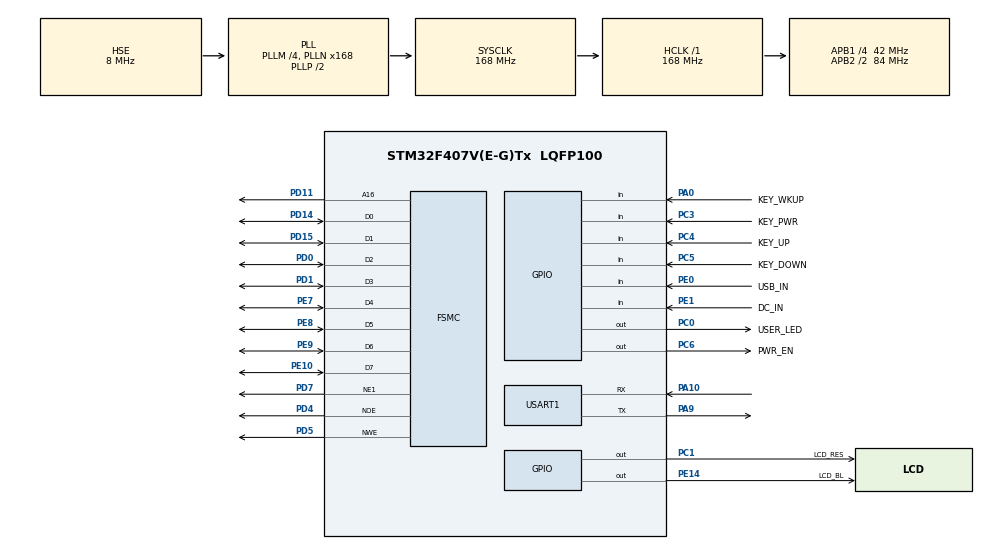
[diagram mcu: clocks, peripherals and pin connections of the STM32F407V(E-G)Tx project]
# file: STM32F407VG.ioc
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FSMC.AddressSetupTime1=1
FSMC.BusTurnAroundDuration1=1
FSMC.DataSetupTime1=5
FSMC.ExtendedAddressSetupTime1=1
FSMC.ExtendedBusTurnAroundDuration1=1
FSMC.ExtendedDataSetupTime1=2
FSMC.ExtendedMode1=FSMC_EXTENDED_MODE_ENABLE
Mcu.Family=STM32F4
Mcu.Name=STM32F407V(E-G)Tx
Mcu.Package=LQFP100
NVIC.PriorityGroup=NVIC_PRIORITYGROUP_4
PA0-WKUP.GPIO_Label=KEY_WKUP
PA0-WKUP.Signal=GPIO_Input
PA10.Mode=Asynchronous
PA10.Signal=USART1_RX
PA13.Mode=Serial_Wire
PA13.Signal=SYS_JTMS-SWDIO
PA14.Mode=Serial_Wire
PA14.Signal=SYS_JTCK-SWCLK
PA9.Mode=Asynchronous
PA9.Signal=USART1_TX
PC0.GPIO_Label=USER_LED
PC0.GPIO_ModeDefaultOutputPP=GPIO_MODE_OUTPUT_PP
PC0.GPIO_PuPd=GPIO_PULLUP
PC0.GPIO_Speed=GPIO_SPEED_FREQ_VERY_HIGH
PC0.PinState=GPIO_PIN_SET
PC0.Signal=GPIO_Output
PC1.GPIO_Label=LCD_RES
PC1.GPIO_PuPd=GPIO_PULLUP
PC1.GPIO_Speed=GPIO_SPEED_FREQ_VERY_HIGH
PC1.PinState=GPIO_PIN_SET
PC1.Signal=GPIO_Output
PC14-OSC32_IN.Mode=LSE-External-Oscillator
PC14-OSC32_IN.Signal=RCC_OSC32_IN
PC15-OSC32_OUT.Mode=LSE-External-Oscillator
PC15-OSC32_OUT.Signal=RCC_OSC32_OUT
PC3.GPIO_Label=KEY_PWR
PC3.GPIO_PuPd=GPIO_PULLUP
PC3.Signal=GPIO_Input
PC4.GPIO_Label=KEY_UP
PC4.GPIO_PuPd=GPIO_PULLUP
PC4.Signal=GPIO_Input
PC5.GPIO_Label=KEY_DOWN
PC5.GPIO_PuPd=GPIO_PULLUP
PC5.Signal=GPIO_Input
PC6.GPIO_Label=PWR_EN
PC6.GPIO_PuPd=GPIO_PULLDOWN
PC6.GPIO_Speed=GPIO_SPEED_FREQ_VERY_HIGH
PC6.PinState=GPIO_PIN_RESET
PC6.Signal=GPIO_Output
PD0.Mode=8b-d1
PD0.Signal=FSMC_D2
PD1.Mode=8b-d1
PD1.Signal=FSMC_D3
PD11.Mode=A16_1
PD11.Signal=FSMC_A16
PD14.Mode=8b-d1
PD14.Signal=FSMC_D0
PD15.Mode=8b-d1
PD15.Signal=FSMC_D1
PD4.Mode=Lcd1
PD4.Signal=FSMC_NOE
PD5.Mode=Lcd1
PD5.Signal=FSMC_NWE
PD7.Mode=NorPsramChipSelect1_1
PD7.Signal=FSMC_NE1
PE0.GPIO_Label=USB_IN
PE0.Signal=GPIO_Input
PE1.GPIO_Label=DC_IN
PE1.Signal=GPIO_Input
PE10.Mode=8b-d1
PE10.Signal=FSMC_D7
PE14.GPIO_Label=LCD_BL
PE14.GPIO_ModeDefaultOutputPP=GPIO_MODE_OUTPUT_PP
PE14.GPIO_PuPd=GPIO_PULLDOWN
PE14.GPIO_Speed=GPIO_SPEED_FREQ_VERY_HIGH
PE14.PinState=GPIO_PIN_RESET
PE14.Signal=GPIO_Output
PE7.Mode=8b-d1
PE7.Signal=FSMC_D4
PE8.Mode=8b-d1
PE8.Signal=FSMC_D5
PE9.Mode=8b-d1
PE9.Signal=FSMC_D6
PH0-OSC_IN.Mode=HSE-External-Oscillator
PH0-OSC_IN.Signal=RCC_OSC_IN
PH1-OSC_OUT.Mode=HSE-External-Oscillator
PH1-OSC_OUT.Signal=RCC_OSC_OUT
ProjectManager.HeapSize=0x200
ProjectManager.StackSize=0x400
ProjectManager.TargetToolchain=MDK-ARM V5.32
RCC.48MHZClocksFreq_Value=84000000
RCC.AHBFreq_Value=168000000
RCC.APB1CLKDivider=RCC_HCLK_DIV4
RCC.APB1Freq_Value=42000000
RCC.APB1TimFreq_Value=84000000
RCC.APB2CLKDivider=RCC_HCLK_DIV2
RCC.APB2Freq_Value=84000000
RCC.APB2TimFreq_Value=168000000
RCC.CortexFreq_Value=168000000
RCC.HCLKFreq_Value=168000000
RCC.HSE_VALUE=8000000
RCC.HSI_VALUE=16000000
RCC.PLLM=4
RCC.PLLN=168
RCC.PLLSourceVirtual=RCC_PLLSOURCE_HSE
RCC.SYSCLKFreq_VALUE=168000000
RCC.SYSCLKSource=RCC_SYSCLKSOURCE_PLLCLK
RCC.VCOOutputFreq_Value=336000000
USART1.VirtualMode=VM_ASYNC
board=custom

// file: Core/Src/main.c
/* USER CODE BEGIN Header */
/**
  ******************************************************************************
  * @file           : main.c
  * @brief          : Main program body
  ******************************************************************************
  * @attention
  *
  * Copyright (c) 2022 STMicroelectronics.
  * All rights reserved.
  *
  * This software is licensed under terms that can be found in the LICENSE file
  * in the root directory of this software component.
  * If no LICENSE file comes with this software, it is provided AS-IS.
  *
  ******************************************************************************
  */
/* USER CODE END Header */
#include "main.h"
#include "usart.h"
#include "gpio.h"
#include "fsmc.h"

/* USER CODE BEGIN Includes */
#include "led.h"
#include "lcd.h"
#include "sys.h"
#include "delay.h"
#include "key.h"
#include "control.h"
/* USER CODE END Includes */

void SystemClock_Config(void);

int main(void)
{
  /* USER CODE BEGIN 1 */
	u8 x=0;
	u16 color_data[21]={WHITE,BLACK,BLUE,BRED,GRED,GBLUE,RED,MAGENTA,GREEN,CYAN,YELLOW,BROWN,BRRED,GRAY,DARKBLUE,LIGHTBLUE,GRAYBLUE,LIGHTGREEN,LGRAY,LGRAYBLUE,LBBLUE};
  /* USER CODE END 1 */

  /* MCU Configuration--------------------------------------------------------*/

  /* Reset of all peripherals, Initializes the Flash interface and the Systick. */
  HAL_Init();

  /* Configure the system clock */
  SystemClock_Config();

  /* USER CODE BEGIN SysInit */
//	SYS_Init();
//	KEY_PWR_Scanf();
  /* USER CODE END SysInit */

  /* Initialize all configured peripherals */
  MX_GPIO_Init();
  MX_USART1_UART_Init();
	MX_FSMC_Init();
  /* USER CODE BEGIN 2 */
	delay_init(168);
	LCD_Init();
  /* USER CODE END 2 */

  /* Infinite loop */
  while (1)
  {

  }
}

void SystemClock_Config(void)
{
  RCC_OscInitTypeDef RCC_OscInitStruct = {0};
  RCC_ClkInitTypeDef RCC_ClkInitStruct = {0};

  /** Configure the main internal regulator output voltage
  */
  __HAL_RCC_PWR_CLK_ENABLE();
  __HAL_PWR_VOLTAGESCALING_CONFIG(PWR_REGULATOR_VOLTAGE_SCALE1);

  /** Initializes the RCC Oscillators according to the specified parameters
  * in the RCC_OscInitTypeDef structure.
  */
  RCC_OscInitStruct.OscillatorType = RCC_OSCILLATORTYPE_HSE;
  RCC_OscInitStruct.HSEState = RCC_HSE_ON;
  RCC_OscInitStruct.PLL.PLLState = RCC_PLL_ON;
  RCC_OscInitStruct.PLL.PLLSource = RCC_PLLSOURCE_HSE;
  RCC_OscInitStruct.PLL.PLLM = 4;
  RCC_OscInitStruct.PLL.PLLN = 168;
  RCC_OscInitStruct.PLL.PLLP = RCC_PLLP_DIV2;
  RCC_OscInitStruct.PLL.PLLQ = 4;
  if (HAL_RCC_OscConfig(&RCC_OscInitStruct) != HAL_OK)
  {
    Error_Handler();
  }

  /** Initializes the CPU, AHB and APB buses clocks
  */
  RCC_ClkInitStruct.ClockType = RCC_CLOCKTYPE_HCLK|RCC_CLOCKTYPE_SYSCLK
                              |RCC_CLOCKTYPE_PCLK1|RCC_CLOCKTYPE_PCLK2;
  RCC_ClkInitStruct.SYSCLKSource = RCC_SYSCLKSOURCE_PLLCLK;
  RCC_ClkInitStruct.AHBCLKDivider = RCC_SYSCLK_DIV1;
  RCC_ClkInitStruct.APB1CLKDivider = RCC_HCLK_DIV4;
  RCC_ClkInitStruct.APB2CLKDivider = RCC_HCLK_DIV2;

  if (HAL_RCC_ClockConfig(&RCC_ClkInitStruct, FLASH_LATENCY_5) != HAL_OK)
  {
    Error_Handler();
  }
}

void Error_Handler(void)
{
  __disable_irq();
  while (1)
  {
  }
}
